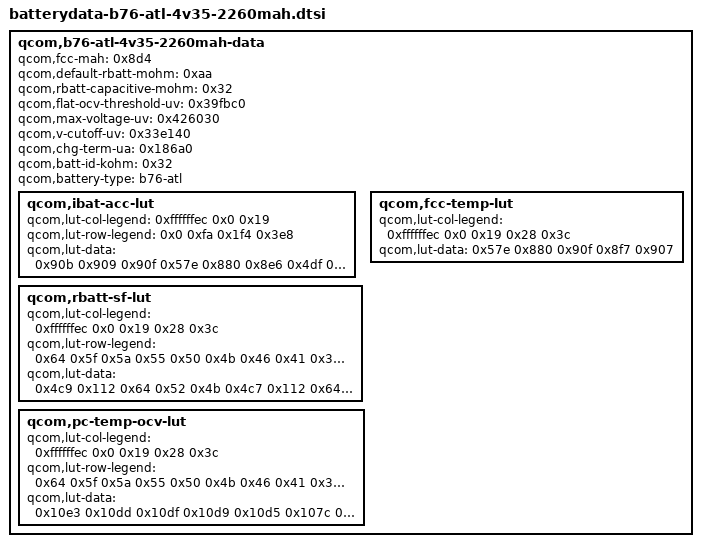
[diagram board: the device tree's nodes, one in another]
/* Copyright (c) 2018, The Linux Foundation. All rights reserved.
*
* This program is free software; you can redistribute it and/or modify
* it under the terms of the GNU General Public License version 2 and
* only version 2 as published by the Free Software Foundation.
*
* This program is distributed in the hope that it will be useful,
* but WITHOUT ANY WARRANTY; without even the implied warranty of
* MERCHANTABILITY or FITNESS FOR A PARTICULAR PURPOSE.  See the
* GNU General Public License for more details.
*/

qcom,b76-atl-4v35-2260mah-data {
	qcom,fcc-mah = <0x8d4>;
	qcom,default-rbatt-mohm = <0xaa>;
	qcom,rbatt-capacitive-mohm = <0x32>;
	qcom,flat-ocv-threshold-uv = <0x39fbc0>;
	qcom,max-voltage-uv = <0x426030>;
	qcom,v-cutoff-uv = <0x33e140>;
	qcom,chg-term-ua = <0x186a0>;
	qcom,batt-id-kohm = <0x32>;
	qcom,battery-type = "b76-atl";

	qcom,ibat-acc-lut {
		qcom,lut-col-legend = <0xffffffec 0x0 0x19>;
		qcom,lut-row-legend = <0x0 0xfa 0x1f4 0x3e8>;
		qcom,lut-data = <0x90b 0x909 0x90f 0x57e 0x880 0x8e6 0x4df 0x6fe 0x8d6 0x2fc 0x404 0x8a6>;
	};

	qcom,rbatt-sf-lut {
		qcom,lut-col-legend = <0xffffffec 0x0 0x19 0x28 0x3c>;
		qcom,lut-row-legend = <0x64 0x5f 0x5a 0x55 0x50 0x4b 0x46 0x41 0x3c 0x37 0x32 0x2d 0x28 0x23 0x1e 0x19 0x14 0x10 0xd 0xb 0xa 0x9 0x8 0x7 0x6 0x5 0x4 0x3 0x2 0x1 0x0>;
		qcom,lut-data = <0x4c9 0x112 0x64 0x52 0x4b 0x4c7 0x112 0x64 0x52 0x4b 0x47b 0x118 0x67 0x54 0x4c 0x442 0x118 0x6b 0x57 0x4d 0x426 0x112 0x70 0x5a 0x4f 0x3f2 0x112 0x74 0x5d 0x51 0x3f5 0x100 0x7a 0x61 0x54 0x3f2 0xfe 0x7e 0x67 0x57 0x3f4 0xfc 0x72 0x65 0x59 0x409 0xfb 0x65 0x55 0x4d 0x435 0xfc 0x64 0x53 0x4c 0x472 0xfc 0x66 0x56 0x4e 0x4bc 0xfb 0x68 0x58 0x50 0x511 0x101 0x6b 0x5a 0x53 0x571 0x111 0x6c 0x59 0x51 0x60b 0x129 0x6b 0x56 0x4d 0x709 0x145 0x6a 0x54 0x4d 0x7dc 0x167 0x69 0x55 0x4c 0x764 0x176 0x65 0x52 0x4b 0x74c 0x17d 0x65 0x53 0x4c 0x7e8 0x18d 0x67 0x54 0x4d 0x89f 0x1a0 0x6a 0x56 0x4f 0x97e 0x1b8 0x6e 0x59 0x50 0xa96 0x1d4 0x73 0x5c 0x52 0xbee 0x1f5 0x76 0x5c 0x52 0xda8 0x214 0x74 0x5a 0x4e 0x1002 0x23d 0x72 0x58 0x4f 0x1352 0x278 0x76 0x5b 0x52 0x18bb 0x2d6 0x7d 0x61 0x56 0x2ceb 0x580 0x91 0x75 0x6f 0x2ceb 0x580 0x91 0x75 0x6f>;
	};

	qcom,fcc-temp-lut {
		qcom,lut-col-legend = <0xffffffec 0x0 0x19 0x28 0x3c>;
		qcom,lut-data = <0x57e 0x880 0x90f 0x8f7 0x907>;
	};

	qcom,pc-temp-ocv-lut {
		qcom,lut-col-legend = <0xffffffec 0x0 0x19 0x28 0x3c>;
		qcom,lut-row-legend = <0x64 0x5f 0x5a 0x55 0x50 0x4b 0x46 0x41 0x3c 0x37 0x32 0x2d 0x28 0x23 0x1e 0x19 0x14 0x10 0xd 0xb 0xa 0x9 0x8 0x7 0x6 0x5 0x4 0x3 0x2 0x1 0x0>;
		qcom,lut-data = <0x10e3 0x10dd 0x10df 0x10d9 0x10d5 0x107c 0x1095 0x10a1 0x109e 0x109a 0x1031 0x105a 0x1069 0x1066 0x1063 0xff0 0x1021 0x1032 0x1030 0x102d 0xfb7 0xfe8 0xfff 0xffd 0xffa 0xf6d 0xfb3 0xfce 0xfcd 0xfca 0xf42 0xf7a 0xfa1 0xfa0 0xf9e 0xf19 0xf52 0xf77 0xf77 0xf75 0xef5 0xf2e 0xf47 0xf4c 0xf4c 0xedc 0xf0e 0xf1c 0xf1d 0xf1d 0xecc 0xef2 0xeff 0xf00 0xeff 0xebf 0xedb 0xee8 0xee9 0xee8 0xeb2 0xec7 0xed5 0xed5 0xed4 0xea3 0xeb8 0xec5 0xec5 0xec3 0xe94 0xead 0xeb7 0xeb4 0xeaf 0xe83 0xe9f 0xea9 0xea2 0xe96 0xe6e 0xe8b 0xe96 0xe8d 0xe80 0xe5a 0xe7a 0xe80 0xe76 0xe69 0xe4c 0xe6e 0xe69 0xe61 0xe55 0xe3f 0xe60 0xe63 0xe5c 0xe50 0xe37 0xe58 0xe61 0xe5a 0xe4f 0xe2c 0xe4e 0xe5f 0xe59 0xe4d 0xe21 0xe4a 0xe5d 0xe57 0xe4b 0xe12 0xe48 0xe5a 0xe53 0xe47 0xe00 0xe47 0xe53 0xe4a 0xe3c 0xde9 0xe44 0xe3e 0xe32 0xe1d 0xdca 0xe41 0xe14 0xe05 0xdee 0xd9d 0xe3d 0xdd9 0xdc8 0xdb1 0xd56 0xdd8 0xd8a 0xd77 0xd5e 0xcd4 0xd3e 0xd13 0xcfa 0xcd7 0xbb8 0xce4 0xbb8 0xbb8 0xbb8>;
	};
};
